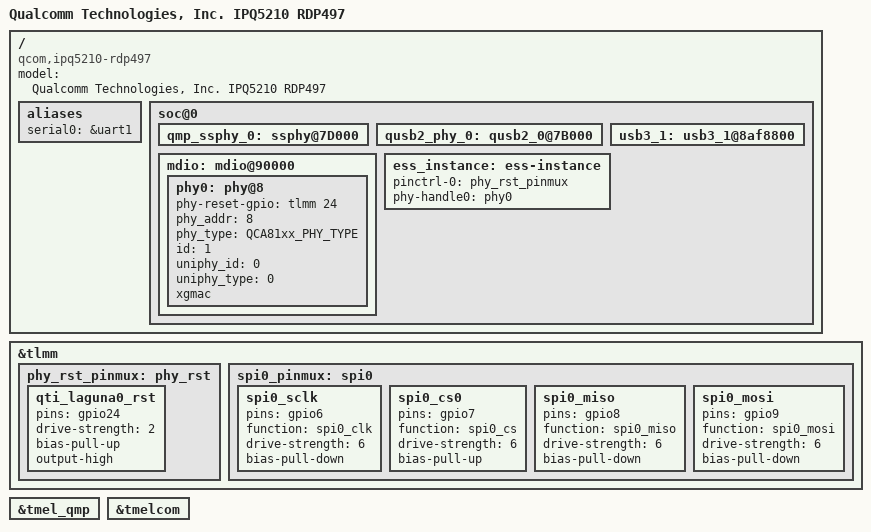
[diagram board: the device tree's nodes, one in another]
// SPDX-License-Identifier: GPL-2.0-only
/*
 * Copyright (c) Qualcomm Technologies, Inc. and/or its subsidiaries.
 */

/dts-v1/;

#include "ipq5210-u-boot.dtsi"

/ {
	model = "Qualcomm Technologies, Inc. IPQ5210 RDP497";
	compatible = "qcom,ipq5210-rdp497", "qcom,ipq5210";

	aliases {
		serial0 = &uart1;
	};

	soc@0 {
		qmp_ssphy_0: ssphy@7D000 {
			status = "okay";
		};

		qusb2_phy_0: qusb2_0@7B000 {
			status = "okay";
		};

		usb3_1: usb3_1@8af8800 {
			status = "okay";
		};

		mdio: mdio@90000 {
			status = "okay";
			phy0: phy@8 {
				phy-reset-gpio = <&tlmm 24 0>;
				phy_addr = <8>;
				phy_type = <QCA81xx_PHY_TYPE>;
				id = <1>;
				uniphy_id = <0>;
				uniphy_type = <0>;
				xgmac;
			};
		};

		ess_instance: ess-instance {
			pinctrl-names = "default";
			pinctrl-0 = <&phy_rst_pinmux>;
			phy-handle0 = <&phy0>;
			status = "okay";
		};
	};
};

&tlmm {
	phy_rst_pinmux: phy_rst {
		qti_laguna0_rst {
			pins = "gpio24";
			drive-strength = <2>;
			bias-pull-up;
			output-high;
		};
	};

	spi0_pinmux: spi0 {
		spi0_sclk {
			pins = "gpio6";
			function = "spi0_clk";
			drive-strength = <6>;
			bias-pull-down;
		};

		spi0_cs0 {
			pins = "gpio7";
			function = "spi0_cs";
			drive-strength = <6>;
			bias-pull-up;
		};

		spi0_miso {
			pins = "gpio8";
			function = "spi0_miso";
			drive-strength = <6>;
			bias-pull-down;
		};

		spi0_mosi {
			pins = "gpio9";
			function = "spi0_mosi";
			drive-strength = <6>;
			bias-pull-down;
		};
	};
};

&tmel_qmp {
	status = "okay";
};

&tmelcom {
	status = "okay";
};
